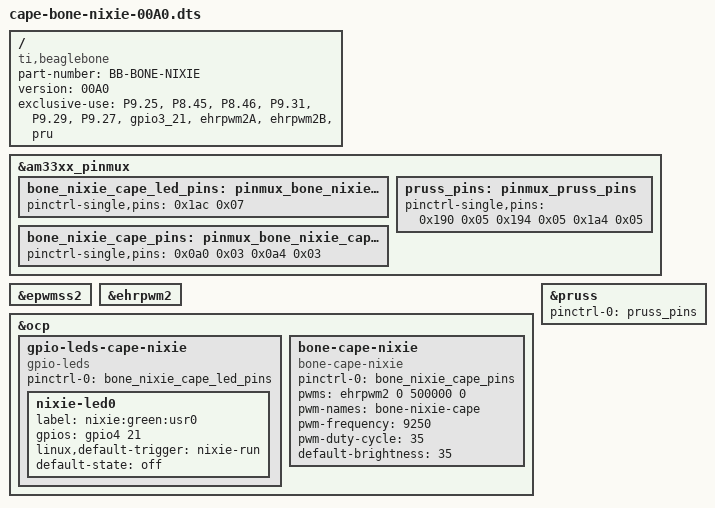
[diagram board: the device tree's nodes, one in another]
/*
* Copyright (C) 2013 Matt Ranostay <mranostay@gmail.com>
*
* This program is free software; you can redistribute it and/or modify
* it under the terms of the GNU General Public License version 2 as
* published by the Free Software Foundation.
*/
/dts-v1/;
/plugin/;

/ {
	compatible = "ti,beaglebone", "ti,beaglebone-black";

	/* identification */
	part-number = "BB-BONE-NIXIE";
	version = "00A0";

	/* state the resources this cape uses */
	exclusive-use =
		/* the pin header uses */
		"P9.25",	/* gpio3_21 */
		"P8.45",	/* ehrpwm2A */
		"P8.46",	/* ehrpwm2B */
		"P9.31",	/* pr1_pru0_pru_r30_0 */
		"P9.29",	/* pr1_pru0_pru_r30_1 */
		"P9.27",	/* pr1_pru0_pru_r30_5 */
		/* the hardware IP uses */
		"gpio3_21",
		"ehrpwm2A", "ehrpwm2B",
		"pru";

	fragment@0 {
		target = <&am33xx_pinmux>;
		__overlay__ {

			bone_nixie_cape_led_pins: pinmux_bone_nixie_cape_led_pins {
				pinctrl-single,pins = <
					0x1ac 0x07	/* mcasp0_ahclkx.gpio3_21, MODE7 */
				>;
			};

			bone_nixie_cape_pins: pinmux_bone_nixie_cape_pins {
				pinctrl-single,pins = <
					0x0a0 0x03      /* lcd_data0.gpio2_6 | MODE3 */
					0x0a4 0x03      /* lcd_data1.gpio2_7 | MODE3 */
				>;
		        };

			pruss_pins: pinmux_pruss_pins {
				pinctrl-single,pins = <
					0x190 0x05	/* mcasp0_aclkx.pr1_pru0_pru_r30_0, MODE5 | DATA */
					0x194 0x05	/* mcasp0_fsx.pr1_pru0_pru_r30_1, MODE5 | LATCH */
					0x1a4 0x05	/* mcasp0_fsr.pr1_pru1_pru_r30_5, MODE5 | CLK */
				>;
			};
		};
	};

	fragment@2 {
		target = <&epwmss2>;
		__overlay__ {
			status = "okay";
		};
	};

	fragment@1 {
		target = <&ehrpwm2>;
		__overlay__ {
			status = "okay";
		};
	};

	fragment@3 {
		target = <&ocp>;
		__overlay__ {

			/* avoid stupid warning */
			#address-cells = <1>;
			#size-cells = <1>;

			gpio-leds-cape-nixie {
				compatible = "gpio-leds";
				pinctrl-names = "default";
				pinctrl-0 = <&bone_nixie_cape_led_pins>;

				nixie-led0 {
					label = "nixie:green:usr0";
					gpios = <&gpio4 21 0>;
					linux,default-trigger = "nixie-run";
					default-state = "off";
				};
			};

			bone-cape-nixie {
				compatible = "bone-cape-nixie";
				status = "okay";

				pinctrl-names = "default";
				pinctrl-0 = <&bone_nixie_cape_pins>;

				pwms = <&ehrpwm2 0 500000 0>;
				pwm-names = "bone-nixie-cape";

				pwm-frequency  = <9250>;	/* 9.250KHz */
				pwm-duty-cycle = <35>;		/* 35% */

				default-brightness = <35>;	/* 35% */
			};
		};
	};

	fragment@4 {
		target = <&pruss>;
		__overlay__ {
			status = "okay";

			pinctrl-names = "default";
			pinctrl-0 = <&pruss_pins>;
		};
	};
};
